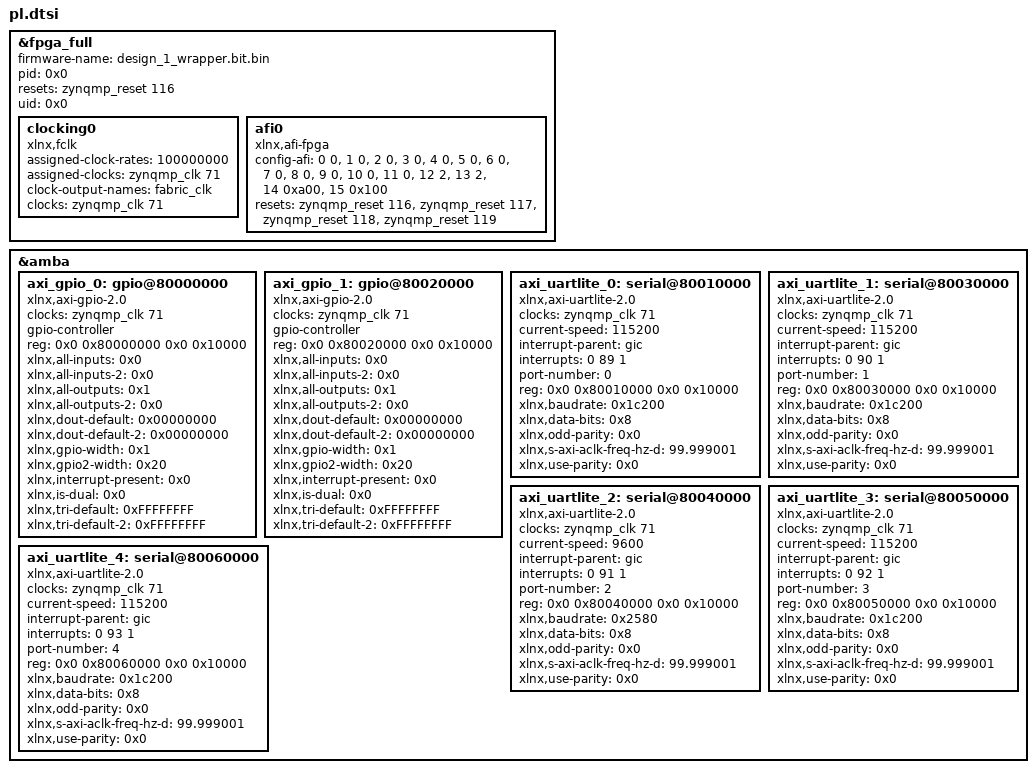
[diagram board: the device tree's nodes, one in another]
/*
 * CAUTION: This file is automatically generated by Xilinx.
 * Version: XSCT 2024.1.1
 * Today is: Tue Jul 30 03:06:34 2024
 */


/dts-v1/;
/plugin/;
&fpga_full {
	firmware-name = "design_1_wrapper.bit.bin";
	pid = <0x0>;
	resets = <&zynqmp_reset 116>;
	uid = <0x0>;
	clocking0: clocking0 {
		#clock-cells = <0>;
		assigned-clock-rates = <100000000>;
		assigned-clocks = <&zynqmp_clk 71>;
		clock-output-names = "fabric_clk";
		clocks = <&zynqmp_clk 71>;
		compatible = "xlnx,fclk";
	};
	afi0: afi0 {
		compatible = "xlnx,afi-fpga";
		config-afi = < 0 0>, <1 0>, <2 0>, <3 0>, <4 0>, <5 0>, <6 0>, <7 0>, <8 0>, <9 0>, <10 0>, <11 0>, <12 2>, <13 2>, <14 0xa00>, <15 0x100>;
		resets = <&zynqmp_reset 116>, <&zynqmp_reset 117>, <&zynqmp_reset 118>, <&zynqmp_reset 119>;
	};
};
&amba {
	#address-cells = <2>;
	#size-cells = <2>;
	axi_gpio_0: gpio@80000000 {
		#gpio-cells = <2>;
		clock-names = "s_axi_aclk";
		clocks = <&zynqmp_clk 71>;
		compatible = "xlnx,axi-gpio-2.0", "xlnx,xps-gpio-1.00.a";
		gpio-controller ;
		reg = <0x0 0x80000000 0x0 0x10000>;
		xlnx,all-inputs = <0x0>;
		xlnx,all-inputs-2 = <0x0>;
		xlnx,all-outputs = <0x1>;
		xlnx,all-outputs-2 = <0x0>;
		xlnx,dout-default = <0x00000000>;
		xlnx,dout-default-2 = <0x00000000>;
		xlnx,gpio-width = <0x1>;
		xlnx,gpio2-width = <0x20>;
		xlnx,interrupt-present = <0x0>;
		xlnx,is-dual = <0x0>;
		xlnx,tri-default = <0xFFFFFFFF>;
		xlnx,tri-default-2 = <0xFFFFFFFF>;
	};
	axi_gpio_1: gpio@80020000 {
		#gpio-cells = <2>;
		clock-names = "s_axi_aclk";
		clocks = <&zynqmp_clk 71>;
		compatible = "xlnx,axi-gpio-2.0", "xlnx,xps-gpio-1.00.a";
		gpio-controller ;
		reg = <0x0 0x80020000 0x0 0x10000>;
		xlnx,all-inputs = <0x0>;
		xlnx,all-inputs-2 = <0x0>;
		xlnx,all-outputs = <0x1>;
		xlnx,all-outputs-2 = <0x0>;
		xlnx,dout-default = <0x00000000>;
		xlnx,dout-default-2 = <0x00000000>;
		xlnx,gpio-width = <0x1>;
		xlnx,gpio2-width = <0x20>;
		xlnx,interrupt-present = <0x0>;
		xlnx,is-dual = <0x0>;
		xlnx,tri-default = <0xFFFFFFFF>;
		xlnx,tri-default-2 = <0xFFFFFFFF>;
	};
	axi_uartlite_0: serial@80010000 {
		clock-names = "s_axi_aclk";
		clocks = <&zynqmp_clk 71>;
		compatible = "xlnx,axi-uartlite-2.0", "xlnx,xps-uartlite-1.00.a";
		current-speed = <115200>;
		device_type = "serial";
		interrupt-names = "interrupt";
		interrupt-parent = <&gic>;
		interrupts = <0 89 1>;
		port-number = <0>;
		reg = <0x0 0x80010000 0x0 0x10000>;
		xlnx,baudrate = <0x1c200>;
		xlnx,data-bits = <0x8>;
		xlnx,odd-parity = <0x0>;
		xlnx,s-axi-aclk-freq-hz-d = "99.999001";
		xlnx,use-parity = <0x0>;
	};
	axi_uartlite_1: serial@80030000 {
		clock-names = "s_axi_aclk";
		clocks = <&zynqmp_clk 71>;
		compatible = "xlnx,axi-uartlite-2.0", "xlnx,xps-uartlite-1.00.a";
		current-speed = <115200>;
		device_type = "serial";
		interrupt-names = "interrupt";
		interrupt-parent = <&gic>;
		interrupts = <0 90 1>;
		port-number = <1>;
		reg = <0x0 0x80030000 0x0 0x10000>;
		xlnx,baudrate = <0x1c200>;
		xlnx,data-bits = <0x8>;
		xlnx,odd-parity = <0x0>;
		xlnx,s-axi-aclk-freq-hz-d = "99.999001";
		xlnx,use-parity = <0x0>;
	};
	axi_uartlite_2: serial@80040000 {
		clock-names = "s_axi_aclk";
		clocks = <&zynqmp_clk 71>;
		compatible = "xlnx,axi-uartlite-2.0", "xlnx,xps-uartlite-1.00.a";
		current-speed = <9600>;
		device_type = "serial";
		interrupt-names = "interrupt";
		interrupt-parent = <&gic>;
		interrupts = <0 91 1>;
		port-number = <2>;
		reg = <0x0 0x80040000 0x0 0x10000>;
		xlnx,baudrate = <0x2580>;
		xlnx,data-bits = <0x8>;
		xlnx,odd-parity = <0x0>;
		xlnx,s-axi-aclk-freq-hz-d = "99.999001";
		xlnx,use-parity = <0x0>;
	};
	axi_uartlite_3: serial@80050000 {
		clock-names = "s_axi_aclk";
		clocks = <&zynqmp_clk 71>;
		compatible = "xlnx,axi-uartlite-2.0", "xlnx,xps-uartlite-1.00.a";
		current-speed = <115200>;
		device_type = "serial";
		interrupt-names = "interrupt";
		interrupt-parent = <&gic>;
		interrupts = <0 92 1>;
		port-number = <3>;
		reg = <0x0 0x80050000 0x0 0x10000>;
		xlnx,baudrate = <0x1c200>;
		xlnx,data-bits = <0x8>;
		xlnx,odd-parity = <0x0>;
		xlnx,s-axi-aclk-freq-hz-d = "99.999001";
		xlnx,use-parity = <0x0>;
	};
	axi_uartlite_4: serial@80060000 {
		clock-names = "s_axi_aclk";
		clocks = <&zynqmp_clk 71>;
		compatible = "xlnx,axi-uartlite-2.0", "xlnx,xps-uartlite-1.00.a";
		current-speed = <115200>;
		device_type = "serial";
		interrupt-names = "interrupt";
		interrupt-parent = <&gic>;
		interrupts = <0 93 1>;
		port-number = <4>;
		reg = <0x0 0x80060000 0x0 0x10000>;
		xlnx,baudrate = <0x1c200>;
		xlnx,data-bits = <0x8>;
		xlnx,odd-parity = <0x0>;
		xlnx,s-axi-aclk-freq-hz-d = "99.999001";
		xlnx,use-parity = <0x0>;
	};
};
